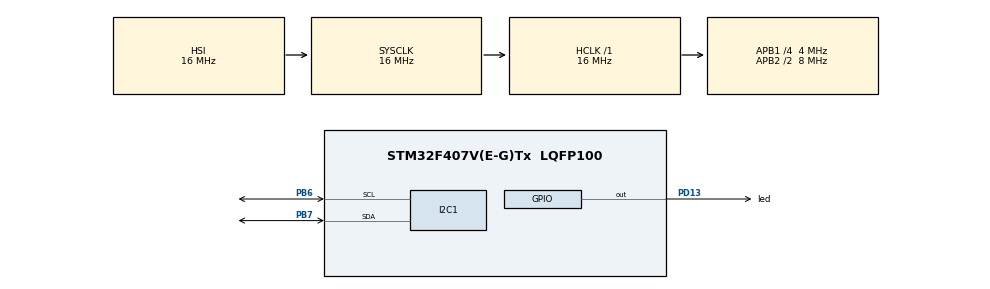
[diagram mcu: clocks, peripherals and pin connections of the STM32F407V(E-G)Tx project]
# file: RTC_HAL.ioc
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Mcu.Family=STM32F4
Mcu.Name=STM32F407V(E-G)Tx
Mcu.Package=LQFP100
NVIC.PriorityGroup=NVIC_PRIORITYGROUP_4
NVIC.RTC_Alarm_IRQn=true\:0\:0\:false\:false\:true\:true\:true\:true
PA13.Mode=Serial_Wire
PA13.Signal=SYS_JTMS-SWDIO
PA14.Mode=Serial_Wire
PA14.Signal=SYS_JTCK-SWCLK
PB6.Mode=I2C
PB6.Signal=I2C1_SCL
PB7.Mode=I2C
PB7.Signal=I2C1_SDA
PD13.GPIO_Label=led
PD13.Signal=GPIO_Output
ProjectManager.HeapSize=0x200
ProjectManager.StackSize=0x400
ProjectManager.TargetToolchain=STM32CubeIDE
RCC.48MHZClocksFreq_Value=48000000
RCC.AHBFreq_Value=16000000
RCC.APB1CLKDivider=RCC_HCLK_DIV4
RCC.APB1Freq_Value=4000000
RCC.APB1TimFreq_Value=8000000
RCC.APB2CLKDivider=RCC_HCLK_DIV2
RCC.APB2Freq_Value=8000000
RCC.APB2TimFreq_Value=16000000
RCC.CortexFreq_Value=16000000
RCC.HCLKFreq_Value=16000000
RCC.HSE_VALUE=25000000
RCC.HSI_VALUE=16000000
RCC.LSE_VALUE=32768
RCC.RCC_RTC_Clock_Source=RCC_RTCCLKSOURCE_LSI
RCC.RCC_RTC_Clock_SourceVirtual=RCC_RTCCLKSOURCE_LSE
RCC.RCC_RTC_Clock_Source_FROM_HSE=RCC_RTCCLKSOURCE_HSE_DIV25
RCC.SYSCLKFreq_VALUE=16000000
RCC.VCOOutputFreq_Value=192000000
RTC.Alarm=RTC_ALARM_A
RTC.AsynchPrediv=127
RTC.Format=RTC_FORMAT_BCD
RTC.Hours=11
RTC.Hours_A=12
RTC.Minutes=32
RTC.Minutes_A=18
RTC.Month=RTC_MONTH_DECEMBER
RTC.Seconds=34
RTC.WeekDay=RTC_WEEKDAY_SUNDAY
RTC.Year=24
VP_RTC_VS_RTC_Activate.Mode=RTC_Enabled
VP_RTC_VS_RTC_Alarm_A_Intern.Mode=Alarm A
VP_RTC_VS_RTC_Calendar.Mode=RTC_Calendar
board=custom

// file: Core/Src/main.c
/* USER CODE BEGIN Header */
/**
  ******************************************************************************
  * @file           : main.c
  * @brief          : STM32 works with RTC
  ******************************************************************************
  * @attention
  *
  * Copyright (c) 2024 STMicroelectronics.
  * All rights reserved.
  *
  * This software is licensed under terms that can be found in the LICENSE file
  * in the root directory of this software component.
  * If no LICENSE file comes with this software, it is provided AS-IS.
  *
  *							REVISION HISTORY
  *	Version 1.0.0: Initial release, read time from internal RTC, display on LCD
  ******************************************************************************
  */
/* USER CODE END Header */
#include "main.h"

/* USER CODE BEGIN Includes */
#include <stdio.h>
#include <string.h>
#include "I2C_LCD.h"
/* USER CODE END Includes */

/* USER CODE BEGIN PD */
#define I2C_SLAVE_ADDRESS 0x4E
/* USER CODE END PD */

/* USER CODE BEGIN PM */
#define led_on 	HAL_GPIO_WritePin(led_GPIO_Port, led_Pin, 1)
/* USER CODE END PM */

I2C_HandleTypeDef hi2c1;

RTC_HandleTypeDef hrtc;

/* USER CODE BEGIN PV */
uint8_t timeData[15];
uint8_t dateData[15];
/* USER CODE END PV */

void SystemClock_Config(void);
static void MX_GPIO_Init(void);
static void MX_RTC_Init(void);
static void MX_I2C1_Init(void);
/* USER CODE BEGIN PFP */
void get_time_date(uint8_t *time, uint8_t *date);
void HAL_RTC_AlarmAEventCallback(RTC_HandleTypeDef *hrtc);
/* USER CODE END PFP */

int main(void)
{

  /* MCU Configuration--------------------------------------------------------*/

  /* Reset of all peripherals, Initializes the Flash interface and the Systick. */
  HAL_Init();

  /* Configure the system clock */
  SystemClock_Config();

  /* Initialize all configured peripherals */
  MX_GPIO_Init();
  MX_RTC_Init();
  MX_I2C1_Init();
  /* USER CODE BEGIN 2 */
  i2c_lcd_init(&hi2c1, I2C_SLAVE_ADDRESS);
  /* USER CODE END 2 */

  /* Infinite loop */
  /* USER CODE BEGIN WHILE */
  while (1)
  {
	  get_time_date(timeData, dateData);
	  i2c_lcd_set_position(&hi2c1, I2C_SLAVE_ADDRESS, 2, 2);
	  i2c_lcd_send_string(&hi2c1, I2C_SLAVE_ADDRESS, dateData);
	  i2c_lcd_set_position(&hi2c1, I2C_SLAVE_ADDRESS, 3, 2);
	  i2c_lcd_send_string(&hi2c1, I2C_SLAVE_ADDRESS, timeData);
	  HAL_Delay(1000);
    /* USER CODE END WHILE */

  }
}

void SystemClock_Config(void)
{
  RCC_OscInitTypeDef RCC_OscInitStruct = {0};
  RCC_ClkInitTypeDef RCC_ClkInitStruct = {0};

  /** Configure the main internal regulator output voltage
  */
  __HAL_RCC_PWR_CLK_ENABLE();
  __HAL_PWR_VOLTAGESCALING_CONFIG(PWR_REGULATOR_VOLTAGE_SCALE1);

  /** Initializes the RCC Oscillators according to the specified parameters
  * in the RCC_OscInitTypeDef structure.
  */
  RCC_OscInitStruct.OscillatorType = RCC_OSCILLATORTYPE_HSI|RCC_OSCILLATORTYPE_LSI;
  RCC_OscInitStruct.HSIState = RCC_HSI_ON;
  RCC_OscInitStruct.HSICalibrationValue = RCC_HSICALIBRATION_DEFAULT;
  RCC_OscInitStruct.LSIState = RCC_LSI_ON;
  RCC_OscInitStruct.PLL.PLLState = RCC_PLL_NONE;
  if (HAL_RCC_OscConfig(&RCC_OscInitStruct) != HAL_OK)
  {
    Error_Handler();
  }

  /** Initializes the CPU, AHB and APB buses clocks
  */
  RCC_ClkInitStruct.ClockType = RCC_CLOCKTYPE_HCLK|RCC_CLOCKTYPE_SYSCLK
                              |RCC_CLOCKTYPE_PCLK1|RCC_CLOCKTYPE_PCLK2;
  RCC_ClkInitStruct.SYSCLKSource = RCC_SYSCLKSOURCE_HSI;
  RCC_ClkInitStruct.AHBCLKDivider = RCC_SYSCLK_DIV1;
  RCC_ClkInitStruct.APB1CLKDivider = RCC_HCLK_DIV4;
  RCC_ClkInitStruct.APB2CLKDivider = RCC_HCLK_DIV2;

  if (HAL_RCC_ClockConfig(&RCC_ClkInitStruct, FLASH_LATENCY_0) != HAL_OK)
  {
    Error_Handler();
  }
}

static void MX_I2C1_Init(void)
{

  hi2c1.Instance = I2C1;
  hi2c1.Init.ClockSpeed = 100000;
  hi2c1.Init.DutyCycle = I2C_DUTYCYCLE_2;
  hi2c1.Init.OwnAddress1 = 0;
  hi2c1.Init.AddressingMode = I2C_ADDRESSINGMODE_7BIT;
  hi2c1.Init.DualAddressMode = I2C_DUALADDRESS_DISABLE;
  hi2c1.Init.OwnAddress2 = 0;
  hi2c1.Init.GeneralCallMode = I2C_GENERALCALL_DISABLE;
  hi2c1.Init.NoStretchMode = I2C_NOSTRETCH_DISABLE;
  if (HAL_I2C_Init(&hi2c1) != HAL_OK)
  {
    Error_Handler();
  }

}

static void MX_RTC_Init(void)
{

  RTC_TimeTypeDef sTime = {0};
  RTC_DateTypeDef sDate = {0};
  RTC_AlarmTypeDef sAlarm = {0};

  /** Initialize RTC Only
  */
  hrtc.Instance = RTC;
  hrtc.Init.HourFormat = RTC_HOURFORMAT_24;
  hrtc.Init.AsynchPrediv = 127;
  hrtc.Init.SynchPrediv = 255;
  hrtc.Init.OutPut = RTC_OUTPUT_DISABLE;
  hrtc.Init.OutPutPolarity = RTC_OUTPUT_POLARITY_HIGH;
  hrtc.Init.OutPutType = RTC_OUTPUT_TYPE_OPENDRAIN;
  if (HAL_RTC_Init(&hrtc) != HAL_OK)
  {
    Error_Handler();
  }

  /* USER CODE BEGIN Check_RTC_BKUP */
  if (HAL_RTCEx_BKUPRead(&hrtc, RTC_BKP_DR1) != 0x32F2) {	// optional value, to backup data
  /* USER CODE END Check_RTC_BKUP */

  /** Initialize RTC and set the Time and Date
  */
  sTime.Hours = 0x11;
  sTime.Minutes = 0x32;
  sTime.Seconds = 0x34;
  sTime.DayLightSaving = RTC_DAYLIGHTSAVING_NONE;
  sTime.StoreOperation = RTC_STOREOPERATION_RESET;
  if (HAL_RTC_SetTime(&hrtc, &sTime, RTC_FORMAT_BCD) != HAL_OK)
  {
    Error_Handler();
  }
  sDate.WeekDay = RTC_WEEKDAY_SUNDAY;
  sDate.Month = RTC_MONTH_DECEMBER;
  sDate.Date = 0x1;
  sDate.Year = 0x24;

  if (HAL_RTC_SetDate(&hrtc, &sDate, RTC_FORMAT_BCD) != HAL_OK)
  {
    Error_Handler();
  }

  HAL_RTCEx_BKUPWrite(&hrtc, RTC_BKP_DR1, 0x32F2);		// optional value, to backup data
  }
  /** Enable the Alarm A
  */
  sAlarm.AlarmTime.Hours = 0x11;
  sAlarm.AlarmTime.Minutes = 0x33;
  sAlarm.AlarmTime.Seconds = 0x0;
  sAlarm.AlarmTime.SubSeconds = 0x0;
  sAlarm.AlarmTime.DayLightSaving = RTC_DAYLIGHTSAVING_NONE;
  sAlarm.AlarmTime.StoreOperation = RTC_STOREOPERATION_RESET;
  sAlarm.AlarmMask = RTC_ALARMMASK_NONE;
  sAlarm.AlarmSubSecondMask = RTC_ALARMSUBSECONDMASK_ALL;
  sAlarm.AlarmDateWeekDaySel = RTC_ALARMDATEWEEKDAYSEL_DATE;
  sAlarm.AlarmDateWeekDay = 0x1;
  sAlarm.Alarm = RTC_ALARM_A;
  if (HAL_RTC_SetAlarm_IT(&hrtc, &sAlarm, RTC_FORMAT_BCD) != HAL_OK)
  {
    Error_Handler();
  }

}

static void MX_GPIO_Init(void)
{
  GPIO_InitTypeDef GPIO_InitStruct = {0};

  /* GPIO Ports Clock Enable */
  __HAL_RCC_GPIOD_CLK_ENABLE();
  __HAL_RCC_GPIOA_CLK_ENABLE();
  __HAL_RCC_GPIOB_CLK_ENABLE();

  /*Configure GPIO pin Output Level */
  HAL_GPIO_WritePin(led_GPIO_Port, led_Pin, GPIO_PIN_RESET);

  /*Configure GPIO pin : led_Pin */
  GPIO_InitStruct.Pin = led_Pin;
  GPIO_InitStruct.Mode = GPIO_MODE_OUTPUT_PP;
  GPIO_InitStruct.Pull = GPIO_NOPULL;
  GPIO_InitStruct.Speed = GPIO_SPEED_FREQ_LOW;
  HAL_GPIO_Init(led_GPIO_Port, &GPIO_InitStruct);

}

/* USER CODE BEGIN 4 */
void get_time_date(uint8_t *time, uint8_t *date)
{
  RTC_DateTypeDef gDate;
  RTC_TimeTypeDef gTime;

  /* Get the RTC current Time */
  HAL_RTC_GetTime(&hrtc, &gTime, RTC_FORMAT_BIN);
  /* Get the RTC current Date */
  HAL_RTC_GetDate(&hrtc, &gDate, RTC_FORMAT_BIN);

  /* Display time Format: hh:mm:ss */
  sprintf((char*)time,"%02d:%02d:%02d", gTime.Hours, gTime.Minutes, gTime.Seconds);
  /* Display date Format: dd-mm-yyyy */
  sprintf((char*)date,"%02d-%02d-%2d", gDate.Date, gDate.Month, 2000 + gDate.Year);
}

void HAL_RTC_AlarmAEventCallback(RTC_HandleTypeDef *hrtc)
{
	led_on;
}
/* USER CODE END 4 */

void Error_Handler(void)
{
  __disable_irq();
  while (1)
  {
  }
}
